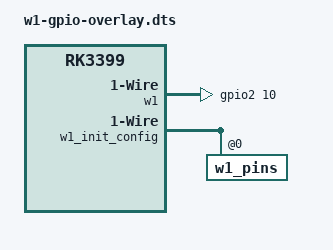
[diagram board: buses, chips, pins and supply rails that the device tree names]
/dts-v1/;
/plugin/;

/ {
    compatible = "rockchip,rk3399-tinker_board_2", "rockchip,rk3399";
    fragment@0 {
        target-path = "/";
        __overlay__ {
            w1: onewire@0 {
                compatible = "w1-gpio";
                pinctrl-names = "default";
                pinctrl-0 = <&w1_pins>;
		// For pin5 GPIO2_B2
                gpios = <&gpio2 10 0>;
                status = "okay";
            };
        };
    };

    fragment@1 {
        target = <&pinctrl>;
        __overlay__ {
	    w1_init_config {
            	w1_pins: w1_pins@0 {
			// For pin5 GPIO2_B2
                	rockchip,pins = <2 10 0 &pcfg_pull_none>;
            	};
	    };
        };
    };
};
